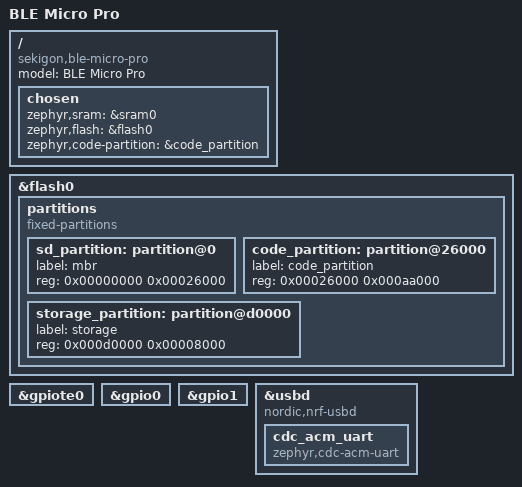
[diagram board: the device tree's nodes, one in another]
/dts-v1/;
#include <nordic/nrf52840_qiaa.dtsi>

/ {
	model = "BLE Micro Pro";
	compatible = "sekigon,ble-micro-pro";

	chosen {
		zephyr,sram = &sram0;
		zephyr,flash = &flash0;
		zephyr,code-partition = &code_partition;
	};
};

&flash0 {
	partitions {
		compatible = "fixed-partitions";
		#address-cells = <1>;
		#size-cells = <1>;

		/*
		 * BOARD 2 layout (QMK daily-driver, S140 SoftDevice still resident
		 * at 0x1000..0x26000). The BMP bootloader places the app right after
		 * the SoftDevice, at 0x26000, so the app must live there. We keep the
		 * SoftDevice in place (it is NOT the cause of the BLE hang — proven on
		 * board 1) to avoid the erase/relocate dance; we only want SWD debug
		 * visibility of the hang here.
		 */
		sd_partition: partition@0 {
			label = "mbr";
			reg = <0x00000000 0x00026000>;
		};

		/*
		 * On-chip evidence: UICR.NRFFW[0] reads 0x000e0000 (logged by
		 * sd_probe as nrffw0=000e0000), i.e. the MBR forwards to a bootloader
		 * region that begins at 0xe0000 — NOT 0xf4000 as we had assumed. Our
		 * old storage at 0xe4000-0xf4000 therefore sat INSIDE the bootloader
		 * region, so the first BLE identity/bond write corrupted the
		 * bootloader and bricked the boot (the total hang we see only with
		 * BLE=y). Move storage well below 0xe0000.
		 */
		code_partition: partition@26000 {
			label = "code_partition";
			reg = <0x00026000 0x000aa000>;   /* 0x26000..0xd0000 */
		};

		storage_partition: partition@d0000 {
			label = "storage";
			reg = <0x000d0000 0x00008000>;   /* 0xd0000..0xd8000, clear of bootloader */
		};
	};
};


/*
 * DIAG: nice!nano's board.dts (the most-used ZMK+nRF52840+BLE board)
 * just does `&gpiote { status = "okay"; }; &gpio0 { status = "okay"; };
 * &gpio1 { status = "okay"; };` with NO explicit gpiote-instance
 * property at all. We had forced BOTH gpio0 and gpio1 onto the same
 * &gpiote0 instance (added earlier for an unrelated build error) —
 * testing whether that static dual-assignment is what's starving BLE
 * of a GPIOTE channel it needs at radio init.
 */
&gpiote0 {
	status = "okay";
};

&gpio0 {
	status = "okay";
};

&gpio1 {
	status = "okay";
};

zephyr_udc0: &usbd {
	compatible = "nordic,nrf-usbd";
	status = "okay";

	cdc_acm_uart: cdc_acm_uart {
		compatible = "zephyr,cdc-acm-uart";
	};
};

/*
 * PRODUCTION: no console chosen (logging off in cocot46lp.conf).
 * To re-enable debug logging: add the LOG/CDC configs in conf (deferred mode
 * ONLY — TWIM + CONFIG_LOG_MODE_IMMEDIATE deadlocks the boot) and restore:
 *   / { chosen { zephyr,console = &cdc_acm_uart; }; };
 */
